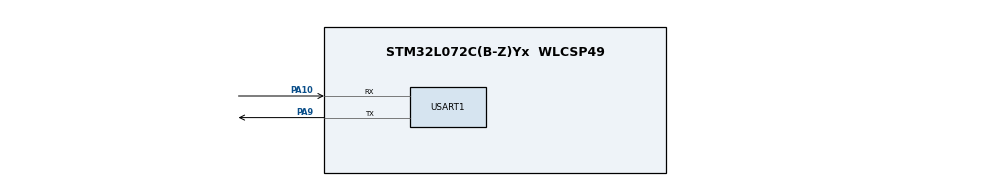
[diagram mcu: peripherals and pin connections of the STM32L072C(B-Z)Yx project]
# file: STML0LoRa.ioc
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Mcu.Family=STM32L0
Mcu.Name=STM32L072C(B-Z)Yx
Mcu.Package=WLCSP49
PA10.GPIO_ModeDefaultPP=GPIO_MODE_AF_PP
PA10.Mode=Asynchronous
PA10.Signal=USART1_RX
PA9.GPIO_ModeDefaultPP=GPIO_MODE_AF_PP
PA9.GPIO_PuPd=GPIO_NOPULL
PA9.Mode=Asynchronous
PA9.Signal=USART1_TX
ProjectManager.HeapSize=0x200
ProjectManager.StackSize=0x400
ProjectManager.TargetToolchain=MDK-ARM V5
RCC.AHBFreq_Value=32000000
RCC.APB1Freq_Value=32000000
RCC.APB1TimFreq_Value=32000000
RCC.APB2Freq_Value=32000000
RCC.APB2TimFreq_Value=32000000
RCC.HCLKFreq_Value=32000000
RCC.HSE_VALUE=8000000
RCC.HSI16_VALUE=16000000
RCC.HSI48_VALUE=48000000
RCC.HSI_VALUE=16000000
RCC.LSE_VALUE=32768
RCC.MSI_VALUE=2097000
RCC.PLLMUL=RCC_PLLMUL_4
RCC.SYSCLKFreq_VALUE=32000000
RCC.SYSCLKSource=RCC_SYSCLKSOURCE_PLLCLK
RCC.VCOOutputFreq_Value=64000000
USART1.VirtualMode-Asynchronous=VM_ASYNC
board=custom

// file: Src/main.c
/**
  ******************************************************************************
  * @file    main.c
  * @author  MCD Application Team
  * @brief   this is the main!
  ******************************************************************************
  * @attention
  *
  * <h2><center>&copy; Copyright (c) 2018 STMicroelectronics.
  * All rights reserved.</center></h2>
  *
  * This software component is licensed by ST under Ultimate Liberty license
  * SLA0044, the "License"; You may not use this file except in compliance with
  * the License. You may obtain a copy of the License at:
  *                             www.st.com/SLA0044
  *
  ******************************************************************************
  */

#include "hw.h"
#include "low_power_manager.h"
#include "lora.h"
#include "bsp.h"
#include "timeServer.h"
#include "vcom.h"
#include "version.h"

#include "string.h"
#include "stdio.h"
#include "main.h"
#include "usart.h"
#include "gpio.h"

#define LORAWAN_MAX_BAT   254

/*!
 * CAYENNE_LPP is myDevices Application server.
 */
//#define CAYENNE_LPP
#define LPP_DATATYPE_DIGITAL_INPUT  0x0
#define LPP_DATATYPE_DIGITAL_OUTPUT 0x1
#define LPP_DATATYPE_HUMIDITY       0x68
#define LPP_DATATYPE_TEMPERATURE    0x67
#define LPP_DATATYPE_BAROMETER      0x73
#define LPP_APP_PORT 99
/*!
 * Defines the application data transmission duty cycle. 5s, value in [ms].
 */
#define APP_TX_DUTYCYCLE                            10000
/*!
 * LoRaWAN Adaptive Data Rate
 * @note Please note that when ADR is enabled the end-device should be static
 */
#define LORAWAN_ADR_STATE LORAWAN_ADR_ON
/*!
 * LoRaWAN Default data Rate Data Rate
 * @note Please note that LORAWAN_DEFAULT_DATA_RATE is used only when ADR is disabled
 */
#define LORAWAN_DEFAULT_DATA_RATE DR_0
/*!
 * LoRaWAN application port
 * @note do not use 224. It is reserved for certification
 */
#define LORAWAN_APP_PORT                            2
/*!
 * LoRaWAN default endNode class port
 */
#define LORAWAN_DEFAULT_CLASS                       CLASS_A
/*!
 * LoRaWAN default confirm state
 */
#define LORAWAN_DEFAULT_CONFIRM_MSG_STATE           LORAWAN_UNCONFIRMED_MSG
/*!
 * User application data buffer size
 */
#define LORAWAN_APP_DATA_BUFF_SIZE                           64
/*!
 * User application data
 */
static uint8_t AppDataBuff[LORAWAN_APP_DATA_BUFF_SIZE];

/*!
 * User application data structure
 */
//static lora_AppData_t AppData={ AppDataBuff,  0 ,0 };
lora_AppData_t AppData = { AppDataBuff,  0, 0 };

extern UART_HandleTypeDef huart1;

/* call back when LoRa endNode has received a frame*/
static void LORA_RxData(lora_AppData_t *AppData);

/* call back when LoRa endNode has just joined*/
static void LORA_HasJoined(void);

/* call back when LoRa endNode has just switch the class*/
static void LORA_ConfirmClass(DeviceClass_t Class);

/* call back when server needs endNode to send a frame*/
static void LORA_TxNeeded(void);

/* callback to get the battery level in % of full charge (254 full charge, 0 no charge)*/
static uint8_t LORA_GetBatteryLevel(void);

/* LoRa endNode send request*/
static void Send(void *context);

/* start the tx process*/
static void LoraStartTx(TxEventType_t EventType);

/* tx timer callback function*/
static void OnTxTimerEvent(void *context);

/* tx timer callback function*/
static void LoraMacProcessNotify(void);

void read(void);
uint8_t data_rx[98];
char buf[100],B1[20],B2[20],B3[20],B4[20],M1[4],M2[4],M3[4],M4[4];
int j=0;

/* load Main call backs structure*/
static LoRaMainCallback_t LoRaMainCallbacks = { LORA_GetBatteryLevel,
                                                HW_GetTemperatureLevel,
                                                HW_GetUniqueId,
                                                HW_GetRandomSeed,
                                                LORA_RxData,
                                                LORA_HasJoined,
                                                LORA_ConfirmClass,
                                                LORA_TxNeeded,
                                                LoraMacProcessNotify
                                              };
LoraFlagStatus LoraMacProcessRequest = LORA_RESET;
LoraFlagStatus AppProcessRequest = LORA_RESET;
/*!
 * Specifies the state of the application LED
 */
static uint8_t AppLedStateOn = RESET;

static TimerEvent_t TxTimer;

#ifdef USE_B_L072Z_LRWAN1
/*!
 * Timer to handle the application Tx Led to toggle
 */
static TimerEvent_t TxLedTimer;
static void OnTimerLedEvent(void *context);
#endif
/* !
 *Initialises the Lora Parameters
 */
static  LoRaParam_t LoRaParamInit = {LORAWAN_ADR_STATE,
                                     LORAWAN_DEFAULT_DATA_RATE,
                                     LORAWAN_PUBLIC_NETWORK
                                    };

/**
  * @brief  Main program
  * @param  None
  * @retval None
  */
int main(void)
{
  /* STM32 HAL library initialization*/
  HAL_Init();

  /* Configure the system clock*/
  SystemClock_Config();

  /* Configure the debug mode*/
//  DBG_Init();

  /* Configure the hardware*/
  HW_Init();

  /* USER CODE BEGIN 1 */
	MX_GPIO_Init();
	MX_USART1_UART_Init();
  /* USER CODE END 1 */

  /*Disbale Stand-by mode*/
  LPM_SetOffMode(LPM_APPLI_Id, LPM_Disable);

  PRINTF("APP_VERSION= %02X.%02X.%02X.%02X\r\n", (uint8_t)(__APP_VERSION >> 24), (uint8_t)(__APP_VERSION >> 16), (uint8_t)(__APP_VERSION >> 8), (uint8_t)__APP_VERSION);
  PRINTF("MAC_VERSION= %02X.%02X.%02X.%02X\r\n", (uint8_t)(__LORA_MAC_VERSION >> 24), (uint8_t)(__LORA_MAC_VERSION >> 16), (uint8_t)(__LORA_MAC_VERSION >> 8), (uint8_t)__LORA_MAC_VERSION);

  /* Configure the Lora Stack*/
  LORA_Init(&LoRaMainCallbacks, &LoRaParamInit);

  LORA_Join();

  LoraStartTx(TX_ON_TIMER) ;

  while (1)
  {

    if (AppProcessRequest == LORA_SET)
    {
      /*reset notification flag*/
      AppProcessRequest = LORA_RESET;
      /*Send*/
			read();
      Send(NULL);
    }
    if (LoraMacProcessRequest == LORA_SET)
    {
      /*reset notification flag*/
      LoraMacProcessRequest = LORA_RESET;
      LoRaMacProcess();
    }
    /*If a flag is set at this point, mcu must not enter low power and must loop*/
    DISABLE_IRQ();

    /* if an interrupt has occurred after DISABLE_IRQ, it is kept pending
     * and cortex will not enter low power anyway  */
    if ((LoraMacProcessRequest != LORA_SET) && (AppProcessRequest != LORA_SET))
    {
#ifndef LOW_POWER_DISABLE
      LPM_EnterLowPower();
#endif
    }

    ENABLE_IRQ();

  }
}

void read(void){
	//HAL_UART_MspInit(&huart3);
	HAL_UART_Receive(&huart1,data_rx,34,10000);
	sprintf(buf,"%s",data_rx);
	//PRINTF("%s",buf);
//	for (j=0;j<17;j++){
//		B1[j] = buf[j];
//		B2[j] = buf[24+j];
//		B3[j] = buf[48+j];
//		B4[j] = buf[72+j];
//	}
	for (j=0;j<3;j++){
		M1[j] = buf[3+j];
		M2[j] = buf[11+j];
		M3[j] = buf[19+j];
		M4[j] = buf[27+j];
	}
	for (j=0;j<strlen(buf);j++){
		buf[j] = 0x0;
	}
	//PRINTF("B1:%s\r",B1);
//	PRINTF("M1:%s M2:%s M3:%s M4:%s\n\r",M1,M2,M3,M4);
//	Send(NULL);
	//HAL_UART_MspDeInit(&huart3);
}

void LoraMacProcessNotify(void)
{
  LoraMacProcessRequest = LORA_SET;
}

static void LORA_HasJoined(void)
{
#if( OVER_THE_AIR_ACTIVATION != 0 )
  PRINTF("JOINED\n\r");
#endif
  LORA_RequestClass(LORAWAN_DEFAULT_CLASS);
}

static void Send(void *context)
{
  /* USER CODE BEGIN 3 */
  uint16_t pressure = 0;
  int16_t temperature = 0;
  uint16_t humidity = 0;
  uint8_t batteryLevel;
  sensor_t sensor_data;

  if (LORA_JoinStatus() != LORA_SET)
  {
    /*Not joined, try again later*/
    LORA_Join();
    return;
  }

//  char message[] = "Hello";
//	char example[15];
//	strcpy(example, M1);
//	strcat(example, M2);
//   strcat(example, M3);
//	strcat(example, M4);
 //set message to AppData.Buff
//	sprintf((char*)AppData.Buff,"M1:%s M2:%s M3:%s M4:%s",M1,M2,M3,M4);
	sprintf((char*)AppData.Buff,"%s%s%s%s",M1,M2,M3,M4);
//	sprintf((char*)AppData.Buff,"%s",message);

 //show in Tera Term
PRINTF((char*)AppData.Buff);

 //set size and port
  AppData.BuffSize = strlen((char*)AppData.Buff);
  AppData.Port = LORAWAN_APP_PORT;

 //Send to LoRaWAN
  LORA_send( &AppData, LORAWAN_DEFAULT_CONFIRM_MSG_STATE);
}

static void LORA_RxData(lora_AppData_t *AppData)
{
  /* USER CODE BEGIN 4 */
  PRINTF("PACKET RECEIVED ON PORT %d\n\r", AppData->Port);

  switch (AppData->Port)
  {
    case 3:
      /*this port switches the class*/
      if (AppData->BuffSize == 1)
      {
        switch (AppData->Buff[0])
        {
          case 0:
          {
            LORA_RequestClass(CLASS_A);
            break;
          }
          case 1:
          {
            LORA_RequestClass(CLASS_B);
            break;
          }
          case 2:
          {
            LORA_RequestClass(CLASS_C);
            break;
          }
          default:
            break;
        }
      }
      break;
    case LORAWAN_APP_PORT:
      if (AppData->BuffSize == 1)
      {
        AppLedStateOn = AppData->Buff[0] & 0x01;
        if (AppLedStateOn == RESET)
        {
          PRINTF("LED OFF\n\r");
          LED_Off(LED_BLUE) ;
        }
        else
        {
          PRINTF("LED ON\n\r");
          LED_On(LED_BLUE) ;
        }
      }
      break;
    case LPP_APP_PORT:
    {
      AppLedStateOn = (AppData->Buff[2] == 100) ?  0x01 : 0x00;
      if (AppLedStateOn == RESET)
      {
        PRINTF("LED OFF\n\r");
        LED_Off(LED_BLUE) ;

      }
      else
      {
        PRINTF("LED ON\n\r");
        LED_On(LED_BLUE) ;
      }
      break;
    }
    default:
      break;
  }
  /* USER CODE END 4 */
}

static void OnTxTimerEvent(void *context)
{
  /*Wait for next tx slot*/
  TimerStart(&TxTimer);

  AppProcessRequest = LORA_SET;
}

static void LoraStartTx(TxEventType_t EventType)
{
  if (EventType == TX_ON_TIMER)
  {
    /* send everytime timer elapses */
    TimerInit(&TxTimer, OnTxTimerEvent);
    TimerSetValue(&TxTimer,  APP_TX_DUTYCYCLE);
    OnTxTimerEvent(NULL);
  }
  else
  {
    /* send everytime button is pushed */
    GPIO_InitTypeDef initStruct = {0};

    initStruct.Mode = GPIO_MODE_IT_RISING;
    initStruct.Pull = GPIO_PULLUP;
    initStruct.Speed = GPIO_SPEED_HIGH;

    HW_GPIO_Init(USER_BUTTON_GPIO_PORT, USER_BUTTON_PIN, &initStruct);
    HW_GPIO_SetIrq(USER_BUTTON_GPIO_PORT, USER_BUTTON_PIN, 0, Send);
  }
}

static void LORA_ConfirmClass(DeviceClass_t Class)
{
  PRINTF("switch to class %c done\n\r", "ABC"[Class]);

  /*Optionnal*/
  /*informs the server that switch has occurred ASAP*/
  AppData.BuffSize = 0;
  AppData.Port = LORAWAN_APP_PORT;

  LORA_send(&AppData, LORAWAN_UNCONFIRMED_MSG);
}

static void LORA_TxNeeded(void)
{
  AppData.BuffSize = 0;
  AppData.Port = LORAWAN_APP_PORT;

  LORA_send(&AppData, LORAWAN_UNCONFIRMED_MSG);
}

/**
  * @brief This function return the battery level
  * @param none
  * @retval the battery level  1 (very low) to 254 (fully charged)
  */
uint8_t LORA_GetBatteryLevel(void)
{
  uint16_t batteryLevelmV;
  uint8_t batteryLevel = 0;

  batteryLevelmV = HW_GetBatteryLevel();

  /* Convert batterey level from mV to linea scale: 1 (very low) to 254 (fully charged) */
  if (batteryLevelmV > VDD_BAT)
  {
    batteryLevel = LORAWAN_MAX_BAT;
  }
  else if (batteryLevelmV < VDD_MIN)
  {
    batteryLevel = 0;
  }
  else
  {
    batteryLevel = (((uint32_t)(batteryLevelmV - VDD_MIN) * LORAWAN_MAX_BAT) / (VDD_BAT - VDD_MIN));
  }

  return batteryLevel;
}

#ifdef USE_B_L072Z_LRWAN1
static void OnTimerLedEvent(void *context)
{
  LED_Off(LED_RED1) ;
}
#endif
/************************ (C) COPYRIGHT STMicroelectronics *****END OF FILE****/
